VERSION "HNPBNYYYYYYYYYYYYYYYYYYYYYYYYYYYNNNNNNNNNN/4/%%%/4/'%**4NNN///"
NS_ :

BS_:

BU_: Sender__XXX imc_BUSFX_2_133754 WC

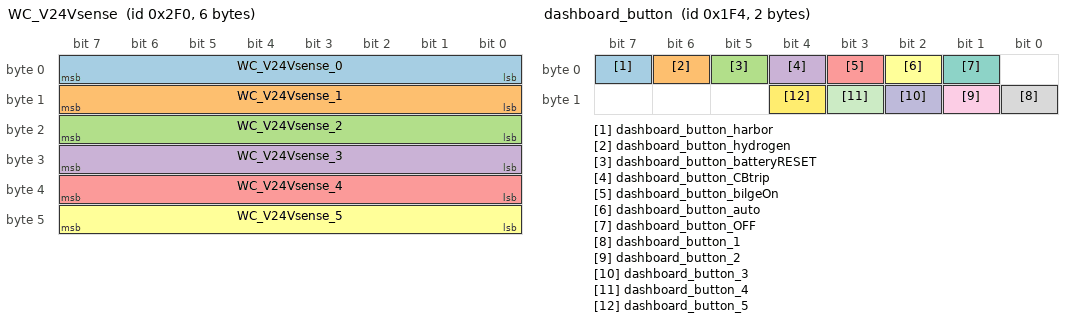
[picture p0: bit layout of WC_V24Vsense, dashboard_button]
BO_ 752 WC_V24Vsense: 6 Sender__XXX
 SG_ WC_V24Vsense_0 : 0|8@1+ (1.176470588E-1,0.000000000E+0) [0.000000000E+0|3.000000000E+1] "V"  imc_BUSFX_2_133754
 SG_ WC_V24Vsense_1 : 8|8@1+ (1.176470588E-1,0.000000000E+0) [0.000000000E+0|3.000000000E+1] "V"  imc_BUSFX_2_133754
 SG_ WC_V24Vsense_2 : 16|8@1+ (1.176470588E-1,0.000000000E+0) [0.000000000E+0|3.000000000E+1] "V"  imc_BUSFX_2_133754
 SG_ WC_V24Vsense_3 : 24|8@1+ (1.176470588E-1,0.000000000E+0) [0.000000000E+0|3.000000000E+1] "V"  imc_BUSFX_2_133754
 SG_ WC_V24Vsense_4 : 32|8@1+ (1.176470588E-1,0.000000000E+0) [0.000000000E+0|3.000000000E+1] "V"  imc_BUSFX_2_133754
 SG_ WC_V24Vsense_5 : 40|8@1+ (1.176470588E-1,0.000000000E+0) [0.000000000E+0|3.000000000E+1] "V"  imc_BUSFX_2_133754

BO_ 500 dashboard_button: 2 Sender__XXX
 SG_ dashboard_button_harbor : 7|1@1+ (1.000000000E+0,0.000000000E+0) [0.000000000E+0|1.000000000E+0] ""  imc_BUSFX_2_133754
 SG_ dashboard_button_hydrogen : 6|1@1+ (1.000000000E+0,0.000000000E+0) [0.000000000E+0|1.000000000E+0] ""  imc_BUSFX_2_133754
 SG_ dashboard_button_batteryRESET : 5|1@1+ (1.000000000E+0,0.000000000E+0) [0.000000000E+0|1.000000000E+0] ""  imc_BUSFX_2_133754
 SG_ dashboard_button_CBtrip : 4|1@1+ (1.000000000E+0,0.000000000E+0) [0.000000000E+0|1.000000000E+0] ""  imc_BUSFX_2_133754
 SG_ dashboard_button_bilgeOn : 3|1@1+ (1.000000000E+0,0.000000000E+0) [0.000000000E+0|1.000000000E+0] ""  imc_BUSFX_2_133754
 SG_ dashboard_button_auto : 2|1@1+ (1.000000000E+0,0.000000000E+0) [0.000000000E+0|1.000000000E+0] ""  imc_BUSFX_2_133754
 SG_ dashboard_button_OFF : 1|1@1+ (1.000000000E+0,0.000000000E+0) [0.000000000E+0|1.000000000E+0] ""  imc_BUSFX_2_133754
 SG_ dashboard_button_1 : 8|1@1- (1.000000000E+0,0.000000000E+0) [-1.000000000E+0|0.000000000E+0] "V"  imc_BUSFX_2_133754
 SG_ dashboard_button_2 : 9|1@1- (1.000000000E+0,0.000000000E+0) [-1.000000000E+0|0.000000000E+0] "V"  imc_BUSFX_2_133754
 SG_ dashboard_button_3 : 10|1@1- (1.000000000E+0,0.000000000E+0) [-1.000000000E+0|0.000000000E+0] "V"  imc_BUSFX_2_133754
 SG_ dashboard_button_4 : 11|1@1- (1.000000000E+0,0.000000000E+0) [-1.000000000E+0|0.000000000E+0] "V"  imc_BUSFX_2_133754
 SG_ dashboard_button_5 : 12|1@1- (1.000000000E+0,0.000000000E+0) [-1.000000000E+0|0.000000000E+0] "V"  imc_BUSFX_2_133754

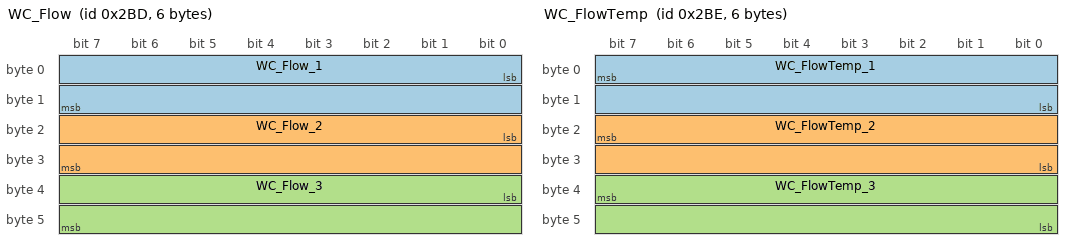
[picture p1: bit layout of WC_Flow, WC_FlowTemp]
BO_ 701 WC_Flow: 6 Sender__XXX
 SG_ WC_Flow_1 : 0|16@1+ (7.814407800E-4,0.000000000E+0) [0.000000000E+0|5.121172152E+1] "L/min"  imc_BUSFX_2_133754
 SG_ WC_Flow_2 : 16|16@1+ (1.221001220E-3,0.000000000E+0) [0.000000000E+0|8.001831495E+1] "L/min"  imc_BUSFX_2_133754
 SG_ WC_Flow_3 : 32|16@1+ (7.814407800E-4,0.000000000E+0) [0.000000000E+0|5.121172152E+1] "L/min"  imc_BUSFX_2_133754

BO_ 702 WC_FlowTemp: 6 Sender__XXX
 SG_ WC_FlowTemp_1 : 7|16@0+ (1.221001220E-3,0.000000000E+0) [0.000000000E+0|8.001831495E+1] "C"  imc_BUSFX_2_133754
 SG_ WC_FlowTemp_2 : 23|16@0+ (1.221001220E-3,0.000000000E+0) [0.000000000E+0|8.001831495E+1] "C"  imc_BUSFX_2_133754
 SG_ WC_FlowTemp_3 : 39|16@0+ (1.221001220E-3,0.000000000E+0) [0.000000000E+0|8.001831495E+1] "C"  imc_BUSFX_2_133754

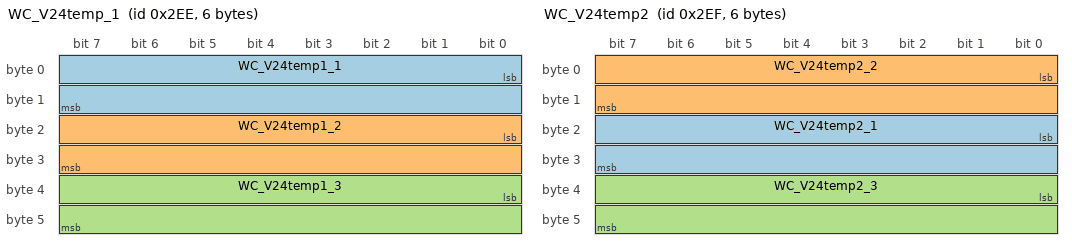
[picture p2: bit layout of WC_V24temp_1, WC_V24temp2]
BO_ 750 WC_V24temp_1: 6 Sender__XXX
 SG_ WC_V24temp1_1 : 0|16@1+ (2.288853280E-3,0.000000000E+0) [0.000000000E+0|1.499999997E+2] "Ã‚Â°C"  imc_BUSFX_2_133754
 SG_ WC_V24temp1_2 : 16|16@1+ (2.288853280E-3,0.000000000E+0) [0.000000000E+0|1.499999997E+2] "Ã‚Â°C"  imc_BUSFX_2_133754
 SG_ WC_V24temp1_3 : 32|16@1+ (2.288853280E-3,0.000000000E+0) [0.000000000E+0|1.499999997E+2] "Ã‚Â°C"  imc_BUSFX_2_133754

BO_ 751 WC_V24temp2: 6 Sender__XXX
 SG_ WC_V24temp2_1 : 16|16@1- (2.288853280E-3,0.000000000E+0) [-7.500114428E+1|7.499885543E+1] "V"  imc_BUSFX_2_133754
 SG_ WC_V24temp2_2 : 0|16@1- (2.288853280E-3,0.000000000E+0) [-7.500114428E+1|7.499885543E+1] "V"  imc_BUSFX_2_133754
 SG_ WC_V24temp2_3 : 32|16@1- (2.288853280E-3,0.000000000E+0) [-7.500114428E+1|7.499885543E+1] "V"  imc_BUSFX_2_133754

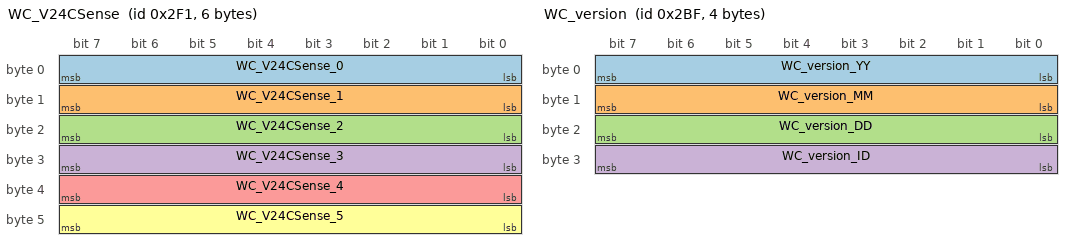
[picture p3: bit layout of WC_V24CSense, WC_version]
BO_ 753 WC_V24CSense: 6 Sender__XXX
 SG_ WC_V24CSense_0 : 0|8@1+ (9.803921568E-2,0.000000000E+0) [0.000000000E+0|2.500000000E+1] "A"  imc_BUSFX_2_133754
 SG_ WC_V24CSense_1 : 8|8@1+ (9.803921568E-2,0.000000000E+0) [0.000000000E+0|2.500000000E+1] "A"  imc_BUSFX_2_133754
 SG_ WC_V24CSense_2 : 16|8@1+ (9.803921568E-2,0.000000000E+0) [0.000000000E+0|2.500000000E+1] "A"  imc_BUSFX_2_133754
 SG_ WC_V24CSense_3 : 24|8@1- (9.803921568E-2,0.000000000E+0) [-1.254901961E+1|1.245098039E+1] "A"  imc_BUSFX_2_133754
 SG_ WC_V24CSense_4 : 32|8@1- (9.803921568E-2,0.000000000E+0) [-1.254901961E+1|1.245098039E+1] "A"  imc_BUSFX_2_133754
 SG_ WC_V24CSense_5 : 40|8@1- (9.803921568E-2,0.000000000E+0) [-1.254901961E+1|1.245098039E+1] "A"  imc_BUSFX_2_133754

BO_ 703 WC_version: 4 WC
 SG_ WC_version_YY : 0|8@1- (1.000000000E+0,0.000000000E+0) [-1.280000000E+2|1.270000000E+2] ""  imc_BUSFX_2_133754
 SG_ WC_version_MM : 8|8@1- (1.000000000E+0,0.000000000E+0) [-1.280000000E+2|1.270000000E+2] ""  imc_BUSFX_2_133754
 SG_ WC_version_DD : 16|8@1- (1.000000000E+0,0.000000000E+0) [-1.280000000E+2|1.270000000E+2] ""  imc_BUSFX_2_133754
 SG_ WC_version_ID : 24|8@1- (1.000000000E+0,0.000000000E+0) [-1.280000000E+2|1.270000000E+2] ""  imc_BUSFX_2_133754

BO_ 1600 HydrogenSensor: 8 Sender__XXX
 SG_ HydrogenSensor_HydrogenLevel : 0|8@1- (2.000000000E-2,0.000000000E+0) [-2.560000000E+0|2.540000000E+0] "%"  imc_BUSFX_2_133754

BO_ 300 EMS_Error: 7 Sender__XXX
 SG_ cell_voltage_extreme_low : 0|1@1- (1.000000000E+0,0.000000000E+0) [-1.000000000E+0|0.000000000E+0] ""  imc_BUSFX_2_133754
 SG_ cell_voltage_extreme_high : 1|1@1- (1.000000000E+0,0.000000000E+0) [-1.000000000E+0|0.000000000E+0] ""  imc_BUSFX_2_133754
 SG_ wizardcontroller_nc : 2|1@1- (1.000000000E+0,0.000000000E+0) [-1.000000000E+0|0.000000000E+0] ""  imc_BUSFX_2_133754
 SG_ steer_nc : 3|1@1- (1.000000000E+0,0.000000000E+0) [-1.000000000E+0|0.000000000E+0] ""  imc_BUSFX_2_133754
 SG_ dashboard_nc : 4|1@1- (1.000000000E+0,0.000000000E+0) [-1.000000000E+0|0.000000000E+0] ""  imc_BUSFX_2_133754
 SG_ hydrogensensor_nc : 5|1@1- (1.000000000E+0,0.000000000E+0) [-1.000000000E+0|0.000000000E+0] ""  imc_BUSFX_2_133754
 SG_ hydrogen_percentage_high : 6|1@1- (1.000000000E+0,0.000000000E+0) [-1.000000000E+0|0.000000000E+0] ""  imc_BUSFX_2_133754
 SG_ emergency_shutdown : 7|1@1- (1.000000000E+0,0.000000000E+0) [-1.000000000E+0|0.000000000E+0] ""  imc_BUSFX_2_133754
 SG_ BMS_nc6 : 8|1@1- (1.000000000E+0,0.000000000E+0) [-1.000000000E+0|0.000000000E+0] ""  imc_BUSFX_2_133754
 SG_ BMS_nc5 : 9|1@1- (1.000000000E+0,0.000000000E+0) [-1.000000000E+0|0.000000000E+0] ""  imc_BUSFX_2_133754
 SG_ BMS_nc4 : 10|1@1- (1.000000000E+0,0.000000000E+0) [-1.000000000E+0|0.000000000E+0] ""  imc_BUSFX_2_133754
 SG_ BMS_nc3 : 11|1@1- (1.000000000E+0,0.000000000E+0) [-1.000000000E+0|0.000000000E+0] ""  imc_BUSFX_2_133754
 SG_ BMS_nc2 : 12|1@1- (1.000000000E+0,0.000000000E+0) [-1.000000000E+0|0.000000000E+0] ""  imc_BUSFX_2_133754
 SG_ BMS_nc1 : 13|1@1- (1.000000000E+0,0.000000000E+0) [-1.000000000E+0|0.000000000E+0] ""  imc_BUSFX_2_133754
 SG_ BMS_nc0 : 14|1@1- (1.000000000E+0,0.000000000E+0) [-1.000000000E+0|0.000000000E+0] ""  imc_BUSFX_2_133754
 SG_ flow_port_openloop_extreme_low : 16|1@1- (1.000000000E+0,0.000000000E+0) [-1.000000000E+0|0.000000000E+0] ""  imc_BUSFX_2_133754
 SG_ flow_starboard_openloop_extreme_ : 17|1@1- (1.000000000E+0,0.000000000E+0) [-1.000000000E+0|0.000000000E+0] ""  imc_BUSFX_2_133754
 SG_ flow_dcdc_extreme_low : 18|1@1- (1.000000000E+0,0.000000000E+0) [-1.000000000E+0|0.000000000E+0] ""  imc_BUSFX_2_133754
 SG_ flow_motor_extreme_low : 19|1@1- (1.000000000E+0,0.000000000E+0) [-1.000000000E+0|0.000000000E+0] ""  imc_BUSFX_2_133754
 SG_ v24_temperature_extreme_high : 20|1@1- (1.000000000E+0,0.000000000E+0) [-1.000000000E+0|0.000000000E+0] ""  imc_BUSFX_2_133754
 SG_ motor_temp_extreme_high : 21|1@1- (1.000000000E+0,0.000000000E+0) [-1.000000000E+0|0.000000000E+0] ""  imc_BUSFX_2_133754
 SG_ cell_temperature_extreme_low : 22|1@1- (1.000000000E+0,0.000000000E+0) [-1.000000000E+0|0.000000000E+0] ""  imc_BUSFX_2_133754
 SG_ cell_temperature_extreme_high : 23|1@1- (1.000000000E+0,0.000000000E+0) [-1.000000000E+0|0.000000000E+0] ""  imc_BUSFX_2_133754
 SG_ temp_battery_loop_extreme_high : 24|1@1- (1.000000000E+0,0.000000000E+0) [-1.000000000E+0|0.000000000E+0] ""  imc_BUSFX_2_133754
 SG_ temp_port_openloop_extreme_high : 25|1@1- (1.000000000E+0,0.000000000E+0) [-1.000000000E+0|0.000000000E+0] ""  imc_BUSFX_2_133754
 SG_ temp_starboard_openloop_extreme_ : 26|1@1- (1.000000000E+0,0.000000000E+0) [-1.000000000E+0|0.000000000E+0] ""  imc_BUSFX_2_133754
 SG_ temp_dcdc_loop_extreme_high : 27|1@1- (1.000000000E+0,0.000000000E+0) [-1.000000000E+0|0.000000000E+0] ""  imc_BUSFX_2_133754
 SG_ temp_fuelcell_loop_extreme_high : 28|1@1- (1.000000000E+0,0.000000000E+0) [-1.000000000E+0|0.000000000E+0] ""  imc_BUSFX_2_133754
 SG_ temp_motor_loop_extreme_high : 29|1@1- (1.000000000E+0,0.000000000E+0) [-1.000000000E+0|0.000000000E+0] ""  imc_BUSFX_2_133754
 SG_ flow_fuel_cell_extreme_low : 30|1@1- (1.000000000E+0,0.000000000E+0) [-1.000000000E+0|0.000000000E+0] ""  imc_BUSFX_2_133754
 SG_ flow_battery_extreme_low : 31|1@1- (1.000000000E+0,0.000000000E+0) [-1.000000000E+0|0.000000000E+0] ""  imc_BUSFX_2_133754
 SG_ v24_temperature_low : 32|1@1- (1.000000000E+0,0.000000000E+0) [-1.000000000E+0|0.000000000E+0] ""  imc_BUSFX_2_133754
 SG_ v24_temperature_high : 33|1@1- (1.000000000E+0,0.000000000E+0) [-1.000000000E+0|0.000000000E+0] ""  imc_BUSFX_2_133754
 SG_ v24_voltage_low : 34|1@1- (1.000000000E+0,0.000000000E+0) [-1.000000000E+0|0.000000000E+0] ""  imc_BUSFX_2_133754
 SG_ v24_voltage_high : 35|1@1- (1.000000000E+0,0.000000000E+0) [-1.000000000E+0|0.000000000E+0] ""  imc_BUSFX_2_133754
 SG_ cell_temperature_low : 36|1@1- (1.000000000E+0,0.000000000E+0) [-1.000000000E+0|0.000000000E+0] ""  imc_BUSFX_2_133754
 SG_ cell_temperature_high : 37|1@1- (1.000000000E+0,0.000000000E+0) [-1.000000000E+0|0.000000000E+0] ""  imc_BUSFX_2_133754
 SG_ cell_voltage_low : 38|1@1- (1.000000000E+0,0.000000000E+0) [-1.000000000E+0|0.000000000E+0] ""  imc_BUSFX_2_133754
 SG_ cell_voltage_high : 39|1@1- (1.000000000E+0,0.000000000E+0) [-1.000000000E+0|0.000000000E+0] ""  imc_BUSFX_2_133754
 SG_ overcurrent : 40|1@1- (1.000000000E+0,0.000000000E+0) [-1.000000000E+0|0.000000000E+0] ""  imc_BUSFX_2_133754
 SG_ motor_temp_high : 41|1@1- (1.000000000E+0,0.000000000E+0) [-1.000000000E+0|0.000000000E+0] ""  imc_BUSFX_2_133754
 SG_ temp_battery_loop_high : 42|1@1- (1.000000000E+0,0.000000000E+0) [-1.000000000E+0|0.000000000E+0] ""  imc_BUSFX_2_133754
 SG_ temp_port_openloop_high : 43|1@1- (1.000000000E+0,0.000000000E+0) [-1.000000000E+0|0.000000000E+0] ""  imc_BUSFX_2_133754
 SG_ temp_starboard_openloop_high : 44|1@1- (1.000000000E+0,0.000000000E+0) [-1.000000000E+0|0.000000000E+0] ""  imc_BUSFX_2_133754
 SG_ temp_dcdc_loop_high : 45|1@1- (1.000000000E+0,0.000000000E+0) [-1.000000000E+0|0.000000000E+0] ""  imc_BUSFX_2_133754
 SG_ temp_fuelcell_loop_high : 46|1@1- (1.000000000E+0,0.000000000E+0) [-1.000000000E+0|0.000000000E+0] ""  imc_BUSFX_2_133754
 SG_ temp_motor_loop_high : 47|1@1- (1.000000000E+0,0.000000000E+0) [-1.000000000E+0|0.000000000E+0] ""  imc_BUSFX_2_133754
 SG_ charge_full : 49|1@1- (1.000000000E+0,0.000000000E+0) [-1.000000000E+0|0.000000000E+0] ""  imc_BUSFX_2_133754
 SG_ FATAL_ERROR : 48|1@1- (1.000000000E+0,0.000000000E+0) [-1.000000000E+0|0.000000000E+0] ""  imc_BUSFX_2_133754

BO_ 301 EMS_FlowTemp: 4 Sender__XXX
 SG_ EMS_FlowTemp_DCDC : 0|16@1+ (2.288853285E-3,0.000000000E+0) [0.000000000E+0|1.500000000E+2] "C"  imc_BUSFX_2_133754
 SG_ EMS_FlowTemp_MotorLoop : 16|16@1+ (2.288853285E-3,0.000000000E+0) [0.000000000E+0|1.500000000E+2] "C"  imc_BUSFX_2_133754

BO_ 302 EMS_Flow: 4 Sender__XXX
 SG_ EMS_Flow_MotorLoop : 0|16@1+ (7.629510948E-4,0.000000000E+0) [0.000000000E+0|5.000000000E+1] "L/min"  imc_BUSFX_2_133754
 SG_ EMS_Flow_DCDC : 16|16@1+ (7.629510948E-4,0.000000000E+0) [0.000000000E+0|5.000000000E+1] "L/min"  imc_BUSFX_2_133754

CM_ "CAN-database created with: imc DEVICES 2.13 Rev. 10";
CM_ BU_ imc_BUSFX_2_133754 "Serial number: 133754
Slot number: 1
Node number: 1";

BA_DEF_ BO_ "GenMsgCycleTimeus" INT 100 60000000;
BA_DEF_ SG_ "SystemSignalLongSymbol" STRING ;

BA_DEF_DEF_  "GenMsgCycleTimeus" 100000;
BA_DEF_DEF_  "SystemSignalLongSymbol" "";

BA_ "SystemSignalLongSymbol" SG_ 300 flow_starboard_openloop_extreme_ "flow_starboard_openloop_extreme_low";
BA_ "SystemSignalLongSymbol" SG_ 300 temp_starboard_openloop_extreme_ "temp_starboard_openloop_extreme_high";
